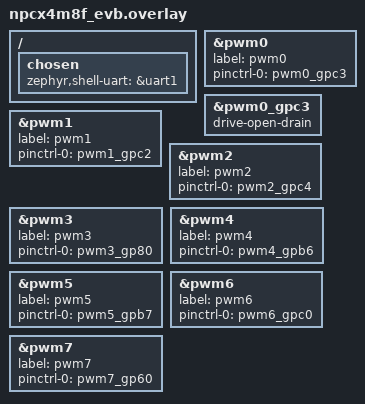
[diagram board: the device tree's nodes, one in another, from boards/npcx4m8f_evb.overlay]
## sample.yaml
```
sample:
  description: Tachometer sensor module sample, the simplest Zephyr application
  name: TACH
common:
    tags: introduction
    integration_platforms:
      - npck3m7k_evb
    harness: console
    harness_config:
      type: multi_line
      regex:
        - "Hello World! (.*)"
```

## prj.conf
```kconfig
CONFIG_SERIAL=y
CONFIG_NATIVE_UART_0_ON_STDINOUT=y
CONFIG_PRINTK=y
CONFIG_UART_INTERRUPT_DRIVEN=y
CONFIG_SHELL=y
CONFIG_SHELL_PROMPT_UART="ec:~$ "
CONFIG_LOG=y
CONFIG_EVENTS=y

CONFIG_PWM=y
CONFIG_SENSOR_LOG_LEVEL_DBG=y
CONFIG_SENSOR=y
CONFIG_TACH_NPCX=y
```

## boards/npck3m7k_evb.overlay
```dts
/*
 * Copyright (c) 2023 Nuvoton Technology Corporation.
 *
 * SPDX-License-Identifier: Apache-2.0
 */


&pwma {
	status = "okay";
	label = "pwm0";
	pinctrl-0 = <&pwma_gp15>;
	pinctrl-names = "default";
};

&pwma_gp15 {
	drive-open-drain;
};

&pwmb {
	status = "okay";
	label = "pwm1";
	pinctrl-0 = <&pwmb_gp21>;
	pinctrl-names = "default";
};

&pwmc {
	status = "okay";
	label = "pwm2";
	pinctrl-0 = <&pwmc_gp13>;
	pinctrl-names = "default";
};

&pwmd {
	status = "okay";
	label = "pwm3";
	pinctrl-0 = <&pwmd_gp32>;
	pinctrl-names = "default";
};

&pwmf {
	status = "okay";
	label = "pwm4";
	pinctrl-0 = <&pwmf_gp40>;
	pinctrl-names = "default";
};

&pwmi {
	status = "okay";
	label = "pwm5";
	pinctrl-0 = <&pwmi_gp72>;
	pinctrl-names = "default";
};

&pwmj {
	status = "okay";
	label = "pwm6";
	pinctrl-0 = <&pwmj_gpd3>;
	pinctrl-names = "default";
};

&pwmk {
	status = "okay";
	label = "pwm7";
	pinctrl-0 = <&pwmk_gp55>;
	pinctrl-names = "default";
};
```

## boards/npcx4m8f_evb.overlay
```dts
/*
 * Copyright (c) 2023 Nuvoton Technology Corporation.
 *
 * SPDX-License-Identifier: Apache-2.0
 */

/ {
	chosen {
		zephyr,shell-uart = &uart1;
	};
};

&pwm0 {
	status = "okay";
	label = "pwm0";
	pinctrl-0 = <&pwm0_gpc3>;
	pinctrl-names = "default";
};

&pwm0_gpc3 {
	drive-open-drain;
};


&pwm1 {
	status = "okay";
	label = "pwm1";
	pinctrl-0 = <&pwm1_gpc2>;
	pinctrl-names = "default";
};

&pwm2 {
	status = "okay";
	label = "pwm2";
	pinctrl-0 = <&pwm2_gpc4>;
	pinctrl-names = "default";
};

&pwm3 {
	status = "okay";
	label = "pwm3";
	pinctrl-0 = <&pwm3_gp80>;
	pinctrl-names = "default";
};

&pwm4 {
	status = "okay";
	label = "pwm4";
	pinctrl-0 = <&pwm4_gpb6>;
	pinctrl-names = "default";
};

&pwm5 {
	status = "okay";
	label = "pwm5";
	pinctrl-0 = <&pwm5_gpb7>;
	pinctrl-names = "default";
};

&pwm6 {
	status = "okay";
	label = "pwm6";
	pinctrl-0 = <&pwm6_gpc0>;
	pinctrl-names = "default";
};

&pwm7 {
	status = "okay";
	label = "pwm7";
	pinctrl-0 = <&pwm7_gp60>;
	pinctrl-names = "default";
};
```

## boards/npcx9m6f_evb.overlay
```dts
/*
 * Copyright (c) 2023 Nuvoton Technology Corporation.
 *
 * SPDX-License-Identifier: Apache-2.0
 */

/ {
	chosen {
		zephyr,shell-uart = &uart1;
};
};
```

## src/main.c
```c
/*
 * Copyright (c) 2023 Nuvoton Technology Corporation.
 *
 * SPDX-License-Identifier: Apache-2.0
 */

#include <zephyr/device.h>
#include <zephyr/kernel.h>
#include <zephyr/pm/policy.h>
#include <zephyr/shell/shell.h>
#include <zephyr/shell/shell_uart.h>
#include <stdlib.h>

/* Target drivers for testing */
#include <zephyr/drivers/sensor.h>
#include <zephyr/drivers/pwm.h>

#define LOG_LEVEL LOG_LEVEL_INF
#include <zephyr/logging/log.h>
LOG_MODULE_REGISTER(main);

#define ARG_CHANNEL 1
#define ARG_PERIOD  2
#define ARG_PLUSE   3
#define ARG_FLAGS   4

/* Objects used for validation */
struct pwm_object {
	const struct device *dev;
	const char *label;
	/* test parameters */
	uint32_t period;
	uint32_t pulse;
	uint32_t flags;
};

/* define your DT nodes' compatible string here */
#define NPCX_PWM_OBJS_INIT(id) {		\
		.dev = DEVICE_DT_GET(id),	\
		.label = DT_PROP(id, label),	\
		.period = 0,			\
		.pulse = 0,			\
		.flags = 0,			\
	},

static struct pwm_object pwm_objs[] = {
	DT_FOREACH_STATUS_OKAY(nuvoton_npcx_pwm, NPCX_PWM_OBJS_INIT)
};


static int pwm_test_set_cycles(uint32_t channel, uint32_t period, uint32_t pulse, pwm_flags_t flags)
{
	/* Record setting */
	pwm_objs[channel].period = period;
	pwm_objs[channel].pulse = pulse;
	pwm_objs[channel].flags = flags;

	LOG_INF("Device_Set : %s, Channel : %d", pwm_objs[channel].label, channel);
	if (pwm_set_cycles(pwm_objs[channel].dev, channel, period, pulse, flags)) {
		LOG_ERR("Fail to set the period and pulse width\n");
		return -EIO;
	}

	return 0;
}

static int pwm_cmd_get_cycles_per_sec(const struct shell *shell, size_t argc, char **argv)
{
	uint64_t cycles_per_sec;
	uint32_t channel = strtoul(argv[ARG_CHANNEL], NULL, 0);

	if (pwm_get_cycles_per_sec(pwm_objs[channel].dev, channel, &cycles_per_sec)) {
		LOG_ERR("Fail to get cycles per sec\n");
		return -EIO;
	}
	LOG_INF("Cycles per sec: %lld", cycles_per_sec);
	return 0;
}

static int pwm_cmd_set(const struct shell *shell, size_t argc, char **argv)
{
	pwm_flags_t flags = 0;
	uint32_t period;
	uint32_t pulse;

	/* Convert integer from string */
	period = strtoul(argv[ARG_PERIOD], NULL, 0);
	pulse = strtoul(argv[ARG_PLUSE], NULL, 0);
	if (argc == (ARG_FLAGS + 1)) {
		flags = strtoul(argv[ARG_FLAGS], NULL, 0);
	}

	if (!strcmp(argv[ARG_CHANNEL], "auto")) {
		/* Set all channels with the same cycles */
		for (int i = 0; i < ARRAY_SIZE(pwm_objs); i++) {
			pwm_test_set_cycles(i, period, pulse, flags);
		}
	} else {
		uint32_t channel = strtoul(argv[ARG_CHANNEL], NULL, 0);

		if (channel >= ARRAY_SIZE(pwm_objs)) {
			return -EINVAL;
		}
		pwm_test_set_cycles(channel, period, pulse, flags);

	}

	return 0;
}

static int pwm_cmd_list(const struct shell *shell, size_t argc, char **argv)
{
	printk("chan\tname\tperiod\tpulse\tflags\n");
	for (int i = 0; i < ARRAY_SIZE(pwm_objs); i++) {
		printk("%d\t%s\t%d\t%d\t%d\n", i,
					pwm_objs[i].label,
					pwm_objs[i].period,
					pwm_objs[i].pulse,
					pwm_objs[i].flags);
	}

	return 0;
}

const struct device *get_tach_device(void)
{
	const struct device *const dev = DEVICE_DT_GET(DT_NODELABEL(tach1));

	if (!device_is_ready(dev)) {
		LOG_INF("Tach not found");
	}

	return dev;
}

static void tach_get_sensor_value(const struct shell *shell, size_t argc, char **argv)
{
	struct sensor_value value;
	const struct device *dev = get_tach_device();

	if (sensor_sample_fetch_chan(dev, SENSOR_CHAN_RPM)) {
		LOG_INF("Sample fetch failed");
	}

	if (sensor_channel_get(dev, SENSOR_CHAN_RPM, &value)) {
		LOG_INF("Get sensor value failed");
	}

	LOG_INF("value = %d", value.val1);
}

#define SLEEP_DELAY_MS	1000
#define SLEEP_DELAY	K_MSEC(SLEEP_DELAY_MS)
static void tach_test(const struct shell *shell, size_t argc, char **argv)
{
	struct sensor_value value;
	const struct device *dev = get_tach_device();

	pwm_test_set_cycles(0, 64000, 60800, 0);

	/* Dummy Read */
	if (sensor_sample_fetch_chan(dev, SENSOR_CHAN_RPM)) {
		LOG_INF("Sample fetch failed");
	}
	if (sensor_channel_get(dev, SENSOR_CHAN_RPM, &value)) {
		LOG_INF("Get sensor value failed");
	}

	k_sleep(SLEEP_DELAY);


	if (sensor_sample_fetch_chan(dev, SENSOR_CHAN_RPM)) {
		LOG_INF("Sample fetch failed");
	}

	if (sensor_channel_get(dev, SENSOR_CHAN_RPM, &value)) {
		LOG_INF("Get sensor value failed");
	}
	LOG_INF("value = %d", value.val1);

	if ((value.val1 > 7410) && (value.val1 < 7869)) {
		LOG_INF("[PASS] TACH test Ok");
	} else {
		LOG_INF("[FAIL] TACH test fail");
	}

	LOG_INF("[GO]\r\n");
}

SHELL_STATIC_SUBCMD_SET_CREATE(sub_tach,
	SHELL_CMD_ARG(pwmlist, NULL, "tach pwmlist - show pwm status", pwm_cmd_list, 0, 0),
	SHELL_CMD_ARG(pwmset, NULL, "tach pwmset <auto/chan> <period> <pulse> <flags>",
			pwm_cmd_set, 5, 0),
	SHELL_CMD_ARG(pwmget, NULL, "tach pwmget <chan> - cycles per sec ",
			pwm_cmd_get_cycles_per_sec, 2, 0),
	SHELL_CMD_ARG(tachget, NULL, "tach tachget - RPM ",
			tach_get_sensor_value, 0, 0),
	SHELL_CMD_ARG(test, NULL, "tach test ",
			tach_test, 0, 0),
	SHELL_SUBCMD_SET_END /* Array terminated. */
);
SHELL_CMD_REGISTER(tach, &sub_tach, "Tach validation commands", NULL);
```
